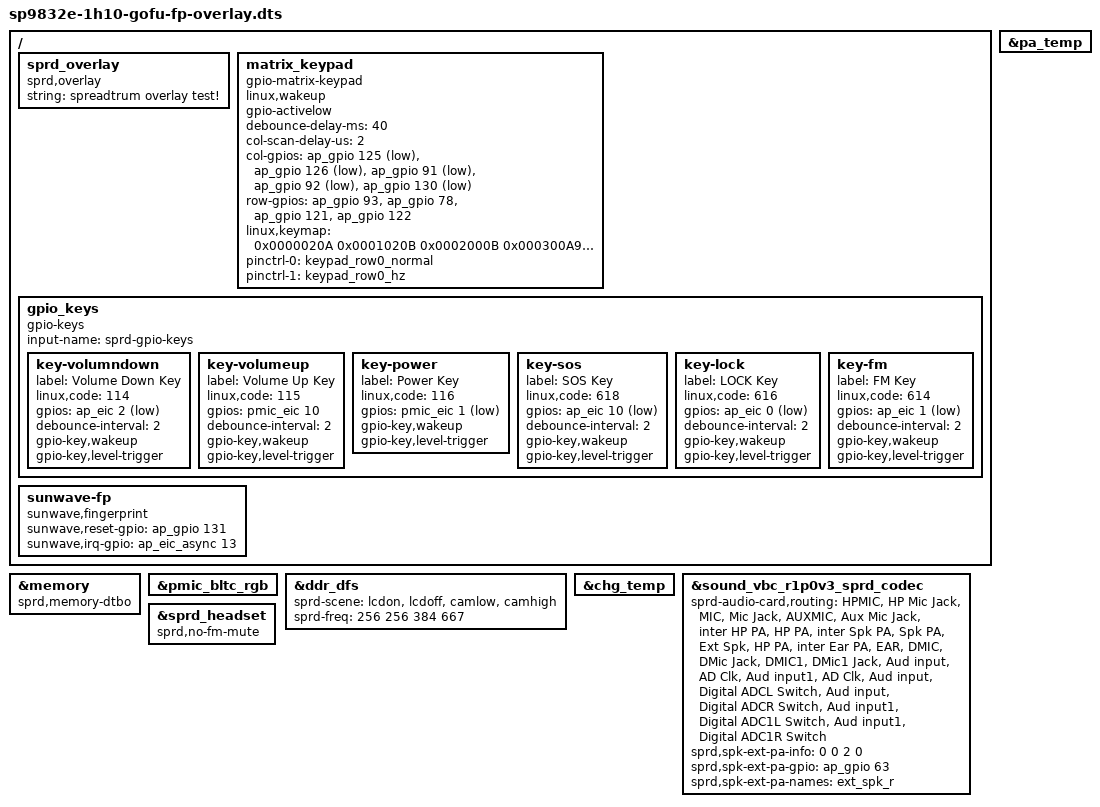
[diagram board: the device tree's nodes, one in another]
/*
 * Spreadtrum sharkle sp9832e board DTS file
 *
 * Copyright (C) 2018, Spreadtrum Communications Inc.
 *
 * This file is licensed under a dual GPLv2 or X11 license.
 */
/dts-v1/;
/plugin/;

#include <dt-bindings/gpio/gpio.h>

/ {
	/*
	* When create a new node, we should use the key word __overlay__,
	* otherwise u-boot can not analyze it.
	*/

	fragment {
		target-path = "/";
		__overlay__ {
			sprd_overlay {
				compatible = "sprd,overlay";
				string = "spreadtrum overlay test!";
			};
			matrix_keypad {
					compatible = "gpio-matrix-keypad";
					status = "okay";
					linux,wakeup;
					gpio-activelow;
					debounce-delay-ms = <40>;
					col-scan-delay-us = <2>;
					col-gpios = <&ap_gpio 125 GPIO_ACTIVE_LOW
					&ap_gpio 126 GPIO_ACTIVE_LOW
					&ap_gpio 91 GPIO_ACTIVE_LOW
					&ap_gpio 92 GPIO_ACTIVE_LOW
					&ap_gpio 130 GPIO_ACTIVE_LOW>;
					row-gpios = <&ap_gpio 93 GPIO_ACTIVE_HIGH
					&ap_gpio 78 GPIO_ACTIVE_HIGH
					&ap_gpio 121 GPIO_ACTIVE_HIGH
					&ap_gpio 122 GPIO_ACTIVE_HIGH>;
					linux,keymap = < 0x0000020A 0x0001020B
									0x0002000B 0x000300A9
									0x0004001C 0x010000B7
									0x010100B8 0x01020038
									0x01030002 0x01040064
									0x02000067 0x0201006C
									0x02020004 0x02030003
									0x02040007 0x03000008
									0x0301000A 0x03020009
									0x03030006  0x03040005
									  >;
					pinctrl-names =
						"row0_normal", "row0_hz";
						pinctrl-0 = <&keypad_row0_normal>;
						pinctrl-1 = <&keypad_row0_hz>;
			};
			gpio_keys {
				compatible = "gpio-keys";
				input-name = "sprd-gpio-keys";
				status = "ok";

				key-volumndown {
					label = "Volume Down Key";
					linux,code = <114>;
					gpios = <&ap_eic 2 1>;
					debounce-interval = <2>;
					gpio-key,wakeup;
					gpio-key,level-trigger;
				};
				key-volumeup {
					label = "Volume Up Key";
					linux,code = <115>;
					gpios = <&pmic_eic 10 0>;
					debounce-interval = <2>;
					gpio-key,wakeup;
					gpio-key,level-trigger;
				};
				key-power {
					label = "Power Key";
					linux,code = <116>;
					gpios = <&pmic_eic 1 1>;
					gpio-key,wakeup;
					gpio-key,level-trigger;
				};
				key-sos {
					label = "SOS Key";
					linux,code = <618>;
					gpios = <&ap_eic 10 1>;
					debounce-interval = <2>;
					gpio-key,wakeup;
					gpio-key,level-trigger;
				};
				key-lock {
					label = "LOCK Key";
					linux,code = <616>;
					gpios = <&ap_eic 0 1>;
					debounce-interval = <2>;
					gpio-key,wakeup;
					gpio-key,level-trigger;
				};
				key-fm {
					label = "FM Key";
					linux,code = <614>;
					gpios = <&ap_eic 1 1>;
					debounce-interval = <2>;
					gpio-key,wakeup;
					gpio-key,level-trigger;
				};
			};

			sunwave-fp {
				compatible = "sunwave,fingerprint";
				sunwave,reset-gpio = <&ap_gpio 131 0 >;
				sunwave,irq-gpio = <&ap_eic_async 13 0 >;
			};
		};
	};
};

/*
 * Sample code. Google strongly recommends you do not use fragment@x and
 * syntax __overlay__, and instead use the reference syntax
*/
&memory {
	compatible = "sprd,memory-dtbo";
};

&pmic_bltc_rgb {
	status = "okay";
};


&ddr_dfs {
	sprd-scene = "lcdon", "lcdoff", "camlow", "camhigh";
	sprd-freq = <256 256 384 667>;
};

&chg_temp {
	status = "okay";
};

&pa_temp {
	status = "okay";
};

&sound_vbc_r1p0v3_sprd_codec {
	sprd-audio-card,routing =
		"HPMIC", "HP Mic Jack",
		"MIC", "Mic Jack",
		"AUXMIC", "Aux Mic Jack",
		"inter HP PA", "HP PA",
		"inter Spk PA", "Spk PA",
		"Ext Spk", "HP PA",
		"inter Ear PA", "EAR",
		"DMIC", "DMic Jack",
		"DMIC1", "DMic1 Jack",

		/* For vbc loopback */
		"Aud input", "AD Clk",
		"Aud input1", "AD Clk",
		"Aud input", "Digital ADCL Switch",
		"Aud input", "Digital ADCR Switch",
		"Aud input1", "Digital ADC1L Switch",
		"Aud input1", "Digital ADC1R Switch";
	/* ext_control_type, hook selection, mode, gpio share */
	sprd,spk-ext-pa-info = <0 0 2 0>;
	sprd,spk-ext-pa-gpio = <&ap_gpio 63 0>;
	sprd,spk-ext-pa-names = "ext_spk_r";
};

&sprd_headset {
	status = "okay";
	sprd,no-fm-mute;
};
